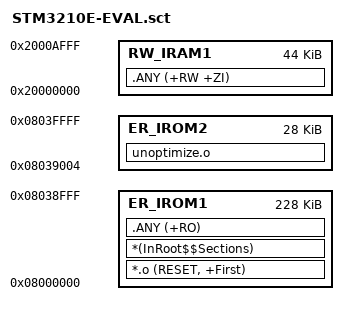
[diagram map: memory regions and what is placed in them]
; *************************************************************
; *** Scatter-Loading Description File generated by uVision ***
; *************************************************************

;本程序使用延迟函数DEV_DelayMs模拟程序运行时间, STM32芯片FLASH预取指缓冲
;会根据地址不同影响指令执行速度, 为保证DEV_DelayMs函数执行时间稳定, 通过
;本链接文件将DEV_DelayMs函数所编译的unoptimize.o文件固定在指定的地址


LR_IROM1 0x08000000 0x00039000  {    ; load region size_region
  ER_IROM1 0x08000000 0x00039000  {  ; load address = execution address
   *.o (RESET, +First)
   *(InRoot$$Sections)
   .ANY (+RO)
  }
  RW_IRAM1 0x20000000 0x0000B000  {  ; RW data
   .ANY (+RW +ZI)
  }
}

;如果你使用的STM32芯片不支持256K字节, 加载程序时会出错, 请将下面的代码全
;部删除即可, 但本程序的执行结果可能会受影响

LR_IROM2 0x08039004 0x00006FFC  {    ; load region size_region
  ER_IROM2 0x08039004 0x00006FFC  {  ; load address = execution address
   unoptimize.o
  }
}

